# STM32MP153x register map
File version: 1.4
Registers are 32-bit, read-write, reset 0x0 unless marked. A register's access mark holds for its fields unless they carry their own. Offsets are from the block's base; [hi:lo] are bit positions; {n}, {i} and the like mark numbered series; 'fields as' and 'values as' point back to an identical list.

## STGENC
Base 0x5C008000
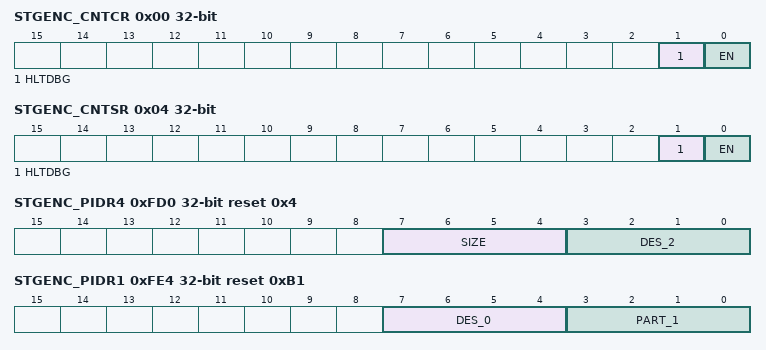
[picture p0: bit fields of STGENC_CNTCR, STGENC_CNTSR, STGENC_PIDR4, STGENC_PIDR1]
0x00 STGENC_CNTCR — STGENC control register
  [1] HLTDBG, [0] EN
0x04 STGENC_CNTSR ro — STGENC status register
  [1] HLTDBG, [0] EN
0x08 STGENC_CNTCVL — the control interface must clear the STGENC_CNTCR.EN bit before writing to this register.
  [31:0] CNTCVL_L_32
0x0C STGENC_CNTCVU — the control interface must clear the STGENC_CNTCR.EN bit before writing to this register.
  [31:0] CNTCVU_U_32
0x20 STGENC_CNTFID0 — the control interface must clear the STGEN_CNTCR.EN bit before writing to this register.
  [31:0] FREQ
0xFD0 STGENC_PIDR4 ro reset 0x4 — STGENC peripheral ID4 register
  [7:4] SIZE, [3:0] DES_2
{0xFC0+4i} STGENC_PIDR{i} ro (i=5..7) — STGENC peripheral ID{i} register
0xFE0 STGENC_PIDR0 ro reset 0x1 — STGENC peripheral ID0 register
  [7:0] PART_0
0xFE4 STGENC_PIDR1 ro reset 0xB1 — STGENC peripheral ID1 register
  [7:4] DES_0, [3:0] PART_1
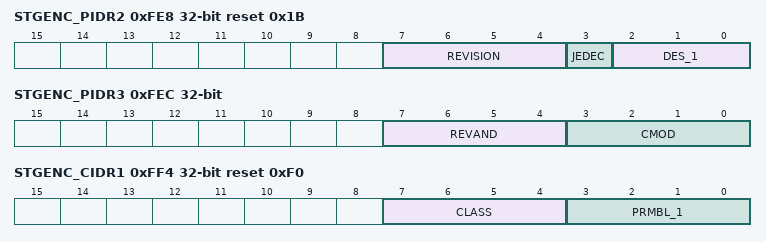
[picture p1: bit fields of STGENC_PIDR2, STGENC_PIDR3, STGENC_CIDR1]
0xFE8 STGENC_PIDR2 ro reset 0x1B — STGENC peripheral ID2 register
  [7:4] REVISION, [3] JEDEC, [2:0] DES_1
0xFEC STGENC_PIDR3 ro — STGENC peripheral ID3 register
  [7:4] REVAND, [3:0] CMOD
0xFF0 STGENC_CIDR0 ro reset 0xD — STGENC component ID0 register
  [7:0] PRMBL_0
0xFF4 STGENC_CIDR1 ro reset 0xF0 — STGENC component ID1 register
  [7:4] CLASS, [3:0] PRMBL_1
0xFF8 STGENC_CIDR2 ro reset 0x50 — STGENC component ID2 register
  [7:0] PRMBL_2
0xFFC STGENC_CIDR3 ro reset 0xB1 — STGENC component ID3 register
  [7:0] PRMBL_3

## STGENR
Base 0x5A005000
Registers as STGENC (with STGENC read as STGENR), without STGENC_CNTCR, STGENC_CNTSR, STGENC_CNTCVL, STGENC_CNTCVU, STGENC_CNTFID0; these are added or differ:
0x00 STGENR_CNTCVL ro — the control interface must clear the STGEN_CNTCR.EN bit before writing to this register.
  [31:0] CNTCVL_L_32
0x04 STGENR_CNTCVU ro — the control interface must clear the STGEN_CNTCR.EN bit before writing to this register.
  [31:0] CNTCVU_U_32

## SYSCFG
Base 0x50020000
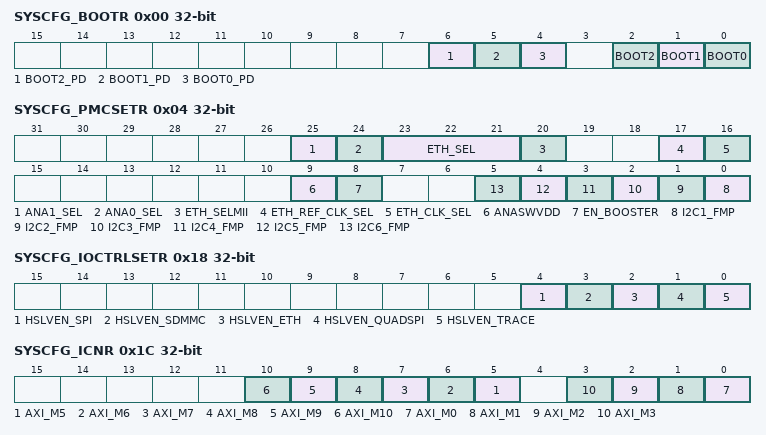
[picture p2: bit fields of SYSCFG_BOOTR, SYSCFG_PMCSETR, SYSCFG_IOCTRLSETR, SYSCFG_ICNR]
0x00 SYSCFG_BOOTR access per field — This register is used to know the state of BOOT pins and to control pull-up to reduce the static power consumption on the pin set to high level. )
  [6] BOOT2_PD rw, [5] BOOT1_PD rw, [4] BOOT0_PD rw, [2] BOOT2 ro, [1] BOOT1 ro, [0] BOOT0 ro
0x04 SYSCFG_PMCSETR — SYSCFG peripheral mode configuration set register
  [25] ANA1_SEL, [24] ANA0_SEL, [23:21] ETH_SEL, [20] ETH_SELMII, [17] ETH_REF_CLK_SEL, [16] ETH_CLK_SEL, [9] ANASWVDD, [8] EN_BOOSTER, [n-1] I2C{n}_FMP (n=1..6)
0x18 SYSCFG_IOCTRLSETR — SYSCFG IO control register
  [4] HSLVEN_SPI, [3] HSLVEN_SDMMC, [2] HSLVEN_ETH, [1] HSLVEN_QUADSPI, [0] HSLVEN_TRACE
0x1C SYSCFG_ICNR — SYSCFG interconnect control register
  [n] AXI_M{n} (n=5..10), [n] AXI_M{n} (n=0..3)
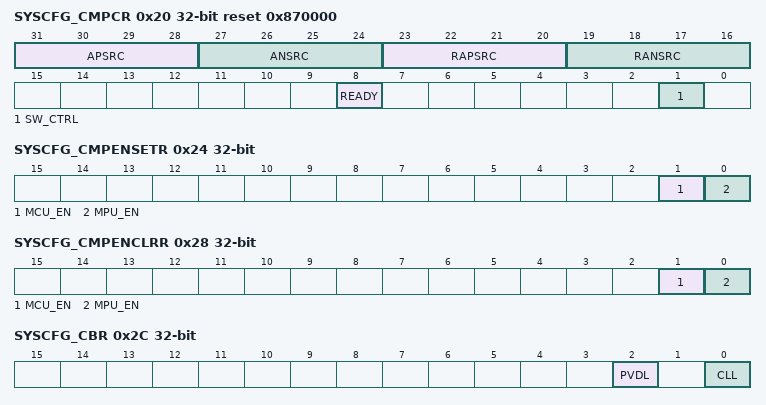
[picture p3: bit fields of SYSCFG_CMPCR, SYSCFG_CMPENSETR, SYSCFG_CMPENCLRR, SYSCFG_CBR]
0x20 SYSCFG_CMPCR access per field reset 0x870000 — SYSCFG compensation cell control register
  [31:28] APSRC ro, [27:24] ANSRC ro, [23:20] RAPSRC rw, [19:16] RANSRC rw, [8] READY ro, [1] SW_CTRL rw
0x24 SYSCFG_CMPENSETR — SYSCFG compensation cell enable set register
  [1] MCU_EN, [0] MPU_EN
0x28 SYSCFG_CMPENCLRR — SYSCFG compensation cell enable set register
  [1] MCU_EN, [0] MPU_EN
0x2C SYSCFG_CBR — SYSCFG control timer break register
  [2] PVDL, [0] CLL
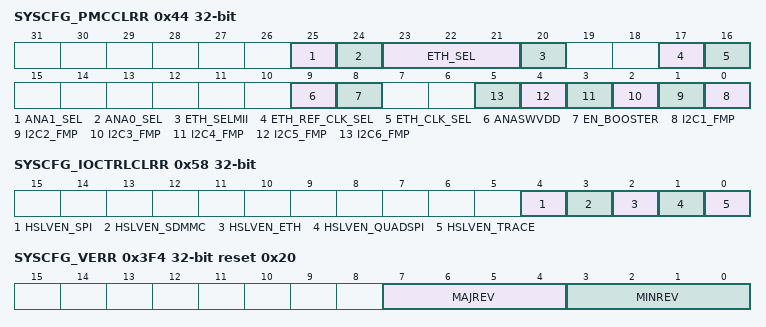
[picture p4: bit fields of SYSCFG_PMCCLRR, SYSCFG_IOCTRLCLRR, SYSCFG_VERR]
0x44 SYSCFG_PMCCLRR — SYSCFG peripheral mode configuration clear register
  fields as SYSCFG_PMCSETR
0x58 SYSCFG_IOCTRLCLRR — SYSCFG IO control register
  fields as SYSCFG_IOCTRLSETR
0x3F4 SYSCFG_VERR ro reset 0x20 — SYSCFG version register
  [7:4] MAJREV, [3:0] MINREV
0x3F8 SYSCFG_IPIDR ro reset 0x30001 — SYSCFG identification register
  [31:0] ID
0x3FC SYSCFG_SIDR ro reset 0xA3C5DD01 — SYSCFG size identification register
  [31:0] SID

## TAMP
Base 0x5C00A000
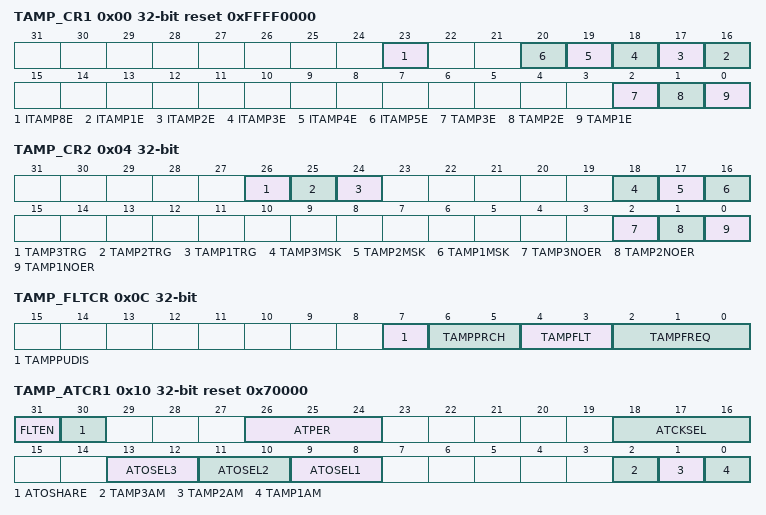
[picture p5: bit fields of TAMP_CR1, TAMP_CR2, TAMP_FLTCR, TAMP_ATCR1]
0x00 TAMP_CR1 reset 0xFFFF0000 — This register can be protected against non-secure access. Refer to Section51.3.3: TAMP secure protection modes.
  [23] ITAMP8E, [n+15] ITAMP{n}E (n=1..5), [2] TAMP3E, [1] TAMP2E, [0] TAMP1E
0x04 TAMP_CR2 — This register can be protected against non-secure access. Refer to Section51.3.3: TAMP secure protection modes.
  [26] TAMP3TRG, [25] TAMP2TRG, [24] TAMP1TRG, [18] TAMP3MSK, [17] TAMP2MSK, [16] TAMP1MSK, [2] TAMP3NOER, [1] TAMP2NOER, [0] TAMP1NOER
0x0C TAMP_FLTCR — This register can be protected against non-secure access. Refer to Section51.3.3: TAMP secure protection modes.
  [7] TAMPPUDIS, [6:5] TAMPPRCH, [4:3] TAMPFLT, [2:0] TAMPFREQ
0x10 TAMP_ATCR1 reset 0x70000 — This register can be protected against non-secure access. Refer to Section51.3.3: TAMP secure protection modes.
  [31] FLTEN, [30] ATOSHARE, [26:24] ATPER, [18:16] ATCKSEL, [13:12] ATOSEL3, [11:10] ATOSEL2, [9:8] ATOSEL1, [2] TAMP3AM, [1] TAMP2AM, [0] TAMP1AM
0x14 TAMP_ATSEEDR wo — This register can be protected against non-secure access. Refer to Section51.3.3: TAMP secure protection modes.
  [31:0] SEED
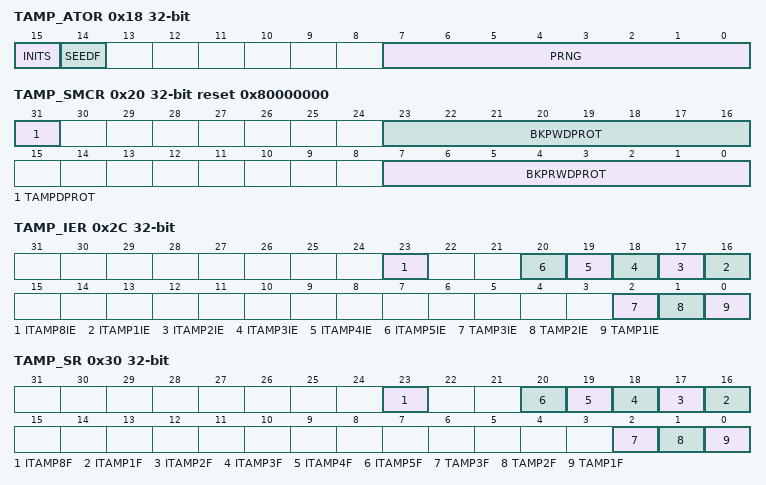
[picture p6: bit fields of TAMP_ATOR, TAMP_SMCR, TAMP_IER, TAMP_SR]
0x18 TAMP_ATOR ro — This register can be protected against non-secure access. Refer to Section51.3.3: TAMP secure protection modes.
  [15] INITS, [14] SEEDF, [7:0] PRNG
0x20 TAMP_SMCR reset 0x80000000 — This register can be written only when the APB access is secure.
  [31] TAMPDPROT, [23:16] BKPWDPROT, [7:0] BKPRWDPROT
0x2C TAMP_IER — This register can be protected against non-secure access. Refer to Section51.3.3: TAMP secure protection modes.
  [23] ITAMP8IE, [n+15] ITAMP{n}IE (n=1..5), [2] TAMP3IE, [1] TAMP2IE, [0] TAMP1IE
0x30 TAMP_SR ro — This register can be protected against non-secure access. Refer to Section51.3.3: TAMP secure protection modes.
  [23] ITAMP8F, [n+15] ITAMP{n}F (n=1..5), [2] TAMP3F, [1] TAMP2F, [0] TAMP1F
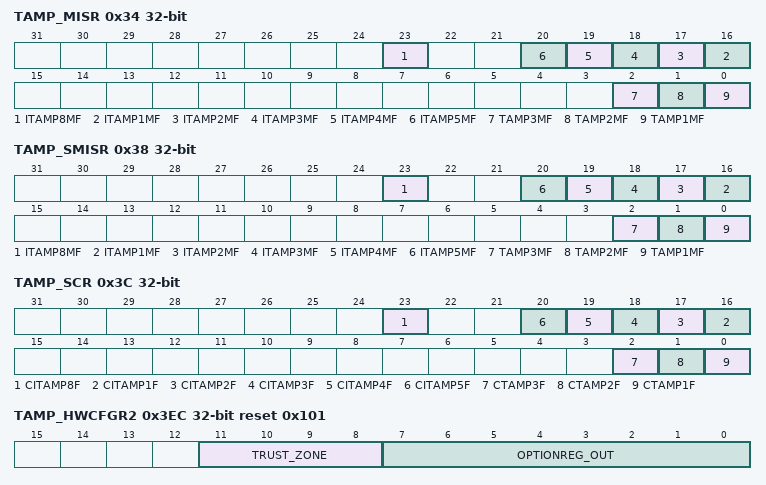
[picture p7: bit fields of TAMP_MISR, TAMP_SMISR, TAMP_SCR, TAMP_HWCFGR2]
0x34 TAMP_MISR ro — TAMP non-secure masked interrupt status register
  [23] ITAMP8MF, [n+15] ITAMP{n}MF (n=1..5), [2] TAMP3MF, [1] TAMP2MF, [0] TAMP1MF
0x38 TAMP_SMISR ro — TAMP secure masked interrupt status register
  fields as TAMP_MISR
0x3C TAMP_SCR wo — TAMP status clear register
  [23] CITAMP8F, [n+15] CITAMP{n}F (n=1..5), [2] CTAMP3F, [1] CTAMP2F, [0] CTAMP1F
0x40 TAMP_COUNTR ro — TAMP monotonic counter register
  [31:0] COUNT
0x50 TAMP_CFGR — TAMP configuration register
  [0] OUT3_RMP
{0x100+4i} TAMP_BKP{i}R (i=0..31) — TAMP backup {i} register
  [31:0] BKP
0x3EC TAMP_HWCFGR2 ro reset 0x101 — TAMP hardware configuration register 2
  [11:8] TRUST_ZONE, [7:0] OPTIONREG_OUT
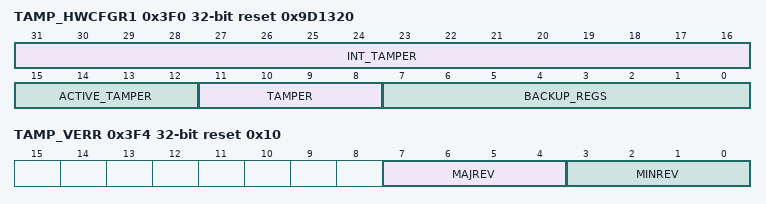
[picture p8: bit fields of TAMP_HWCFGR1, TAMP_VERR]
0x3F0 TAMP_HWCFGR1 ro reset 0x9D1320 — TAMP hardware configuration register 1
  [31:16] INT_TAMPER, [15:12] ACTIVE_TAMPER, [11:8] TAMPER, [7:0] BACKUP_REGS
0x3F4 TAMP_VERR ro reset 0x10 — TAMP version register
  [7:4] MAJREV, [3:0] MINREV
0x3F8 TAMP_IPIDR ro reset 0x121033 — TAMP identification register
  [31:0] ID
0x3FC TAMP_SIDR ro reset 0xA3C5DD01 — TAMP size identification register
  [31:0] SID

## Notices in the file
Copyright (c) 2024 STMicroelectronics.
SPDX-License-Identifier: Apache-2.0
Licensed under the Apache License, Version 2.0 (the "License");
you may not use this file except in compliance with the License.
You may obtain a copy of the License at
http://www.apache.org/licenses/LICENSE-2.0
Unless required by applicable law or agreed to in writing, software
distributed under the License is distributed on an "AS IS" BASIS,
WITHOUT WARRANTIES OR CONDITIONS OF ANY KIND, either express or implied.
See the License for the specific language governing permissions and
limitations under the License.
